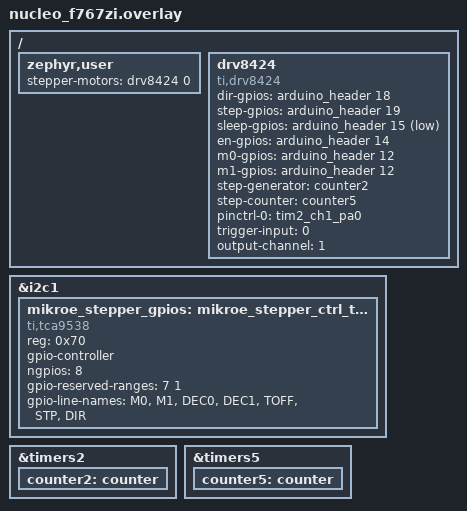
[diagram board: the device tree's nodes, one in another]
/*
 * Copyright (c) 2024 Navimatix GmbH
 * SPDX-License-Identifier: Apache-2.0
 */

#include <zephyr/dt-bindings/gpio/gpio.h>

/ {
	zephyr,user {
		stepper-motors = <&drv8424 0>;
	};
};

&i2c1 {
	status = "okay";

	mikroe_stepper_gpios: mikroe_stepper_ctrl_tca9538a@70 {
		status = "okay";
		compatible = "ti,tca9538";

		reg = <0x70>;

		gpio-controller;
		ngpios = <8>;
		#gpio-cells = <2>;

		gpio-reserved-ranges = <7 1>;

		gpio-line-names =
			"M0",
			"M1",
			"DEC0",
			"DEC1",
			"TOFF",
			"STP",
			"DIR";
	};
};

/ {
	 drv8424: drv8424 {
		status = "okay";
		compatible = "ti,drv8424";

		dir-gpios = <&arduino_header 18 0>; /* D12 */
		step-gpios = <&arduino_header 19 0>; /* D13 */
		sleep-gpios = <&arduino_header 15 GPIO_ACTIVE_LOW>; /* D9 */
		en-gpios  = <&arduino_header 14 0>; /* D8 */
		// m0-gpios = <&mikroe_stepper_gpios 0 0>;
		// m1-gpios = <&mikroe_stepper_gpios 1 0>;
		m0-gpios = <&arduino_header 12 0>;
		m1-gpios = <&arduino_header 12 0>;
		// counter = <&counter2>;
		step-generator = <&counter2>;
		step-counter = <&counter5>;

		pinctrl-0 = < &tim2_ch1_pa0 >;
		pinctrl-names = "default";
		trigger-input = <0>;
		output-channel = <1>;

		#address-cells = <1>;
		#size-cells = <0>;
		#stepper-motor-cells = <0>;
	};
};

&timers2 {
	status = "okay";
	counter2: counter {
		status = "okay";
	};

	// pwm2: pwm{
	// 	status = "okay";
	// 	pinctrl-0 = < &tim2_ch1_pa0 >;
	// 	pinctrl-names = "default";
	// };
};

&timers5 {
	status = "okay";
	counter5: counter {
		status = "okay";
	};
};
